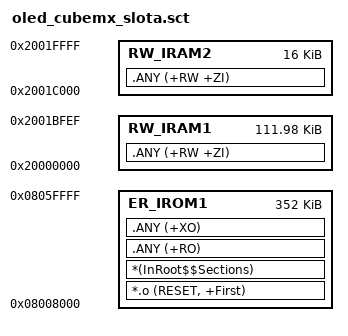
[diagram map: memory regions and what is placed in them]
; *************************************************************
; *** APP Slot A Scatter File — ROM: 0x08008000, 352KB (S2~S6)
; *** 替代 oled_cubemx/MDK-ARM/oled_cubemx/oled_cubemx.sct
; *************************************************************

LR_IROM1 0x08008000 0x00058000  {    ; load region size_region (352KB)
  ER_IROM1 0x08008000 0x00058000  {  ; load address = execution address
    *.o (RESET, +First)
    *(InRoot$$Sections)
    .ANY (+RO)
    .ANY (+XO)
  }
  RW_IRAM1 0x20000000 0x0001BFF0  {  ; RW data (112KB - 16B NOINIT)
    .ANY (+RW +ZI)
  }
  RW_IRAM2 0x2001C000 0x00004000  {
    .ANY (+RW +ZI)
  }
}
